# N32F030 register map
File version: 1.0
Registers are 32-bit, read-write, reset 0x0 unless marked. A register's access mark holds for its fields unless they carry their own. Offsets are from the block's base; [hi:lo] are bit positions.

## CLK — CLK Register Map
Base 0x50000200
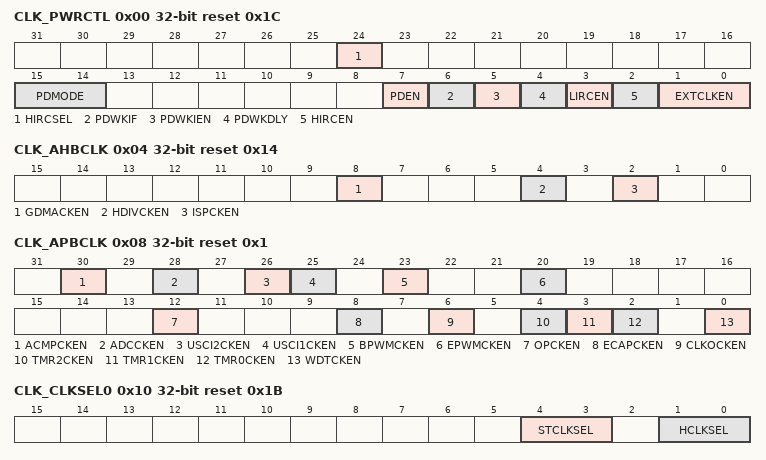
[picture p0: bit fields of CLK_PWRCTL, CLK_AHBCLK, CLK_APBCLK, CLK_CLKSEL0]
0x00 CLK_PWRCTL reset 0x1C — System Power-down Control Register
  [24] HIRCSEL — 0: Internal High Speed RC Oscillator Clock Will Output 48MHz. 1: Internal high speed RC oscillator clock will output 60MHz
  [15:14] PDMODE — 00: LDO Off When Power Down Mode. 01: LDO on when power down node
  [7] PDEN — System Power-down Enable Control (Write Protect). When this bit is set to 1, Power-down mode is enabled. When chip wakes up from Power-down mode, this bit is auto cleared. Users need to set this bit again for next Power-down. In Power-down mode, EXT_CLK and HIRC will be disabled. In Power-down mode, the system clocks are disabled, and ignored the clock source selection. The clocks of peripheral are not controlled by Power-down mode if the peripheral clock source is from LIRC. LIRC is controlled by bit LIRCEN. Note: This bit is write protected. Refer to the SYS_REGLCTL register.
    0=Chip operating normally or chip in idle mode because of WFI/WFE command; 1=Chip enters Power-down mode when CPU sleep command WFI/WFE
  [6] PDWKIF — Power-down Mode Wake-up Interrupt Status. Set by 'Power-down wake-up event', it indicates that resume from 'Power-down mode' The flag is set if the GPIO, USCIx, WDT, ACMPx, BOD, TMRx wake-up occurred. Note1: Write 1 to clear the bit to 0. Note2: This bit works only if PDWKIEN (CLK_PWRCTL[5]) set to 1.
  [5] PDWKIEN — Power-down Mode Wake-up Interrupt Enable Control (Write Protect). Note1: The interrupt will occur when both PDWKIF and PDWKIEN are high. Note2: This bit is write protected. Refer to the SYS_REGLCTL register.
    0=Power-down mode wake-up interrupt Disabled; 1=Power-down mode wake-up interrupt Enabled
  [4] PDWKDLY — Wake-up Delay Counter Enable Control (Write Protect). When the chip wakes up from Power-down mode, the clock control will delay certain clock cycles to wait system clock stable. The delayed clock cycle is 4096 clock cycles when chip works at external clock input(EXT_CLK), and 256 clock cycles when chip works at 48(60) MHz internal high speed RC oscillator (HIRC). Note: This bit is write protected. Refer to the SYS_REGLCTL register.
    0=Clock cycles delay Disabled; 1=Clock cycles delay Enabled
  [3] LIRCEN — LIRC Enable Control (Write Protect). Note: This bit is write protected. Refer to the SYS_REGLCTL register.
    0=10 kHz internal low speed RC oscillator (LIRC) Disabled; 1=10 kHz internal low speed RC oscillator (LIRC) Enabled
  [2] HIRCEN — HIRC Enable Control (Write Protect). Note: This bit is write protected. Refer to the SYS_REGLCTL register.
    0=48(60) MHz internal high speed RC oscillator (HIRC) Disabled; 1=48(60) MHz internal high speed RC oscillator (HIRC) Enabled
  [1:0] EXTCLKEN — External Clock Enable Control (Write Protect). These two bits are default set to '00' and EXT_CLK(PC.3) pins are GPIO. Note: This bit is write protected. Refer to the SYS_REGLCTL register.
    0=Disable external EXT_CLK; 3=Enable external EXT_CLK
0x04 CLK_AHBCLK reset 0x14 — AHB Devices Clock Enable Control Register
  [8] GDMACKEN — Gereral Direct Memory Access Controller Clock Enable Control
    0=GDMA clock Disabled; 1=GDMA clock Enabled
  [4] HDIVCKEN — Hardware Divider Controller Clock Enable Control
    0=HDIV peripheral clock Disabled; 1=HDIV peripheral clock Enabled
  [2] ISPCKEN — Flash ISP Controller Clock Enable Control
    0=Flash ISP peripheral clock Disabled; 1=Flash ISP peripheral clock Enabled
0x08 CLK_APBCLK reset 0x1 — APB Devices Clock Enable Control Register
  [30] ACMPCKEN — Analog Comparator Clock Enable Control
    0=Analog comparator clock Disabled; 1=Analog comparator clock Enabled
  [28] ADCCKEN — Analog-digital-converter (ADC) Clock Enable Control
    0=ADC clock Disabled; 1=ADC clock Enabled
  [26] USCI2CKEN — USCI2 Clock Enable Control
    0=USCI2 clock Disabled; 1=USCI2 clock Enabled
  [25] USCI1CKEN — USCI1 Clock Enable Control
    0=USCI1 clock Disabled; 1=USCI1 clock Enabled
  [23] BPWMCKEN — Basic PWM Channel 0/1 Clock Enable Control
    0=BBPWM channel 0/1 clock Disabled; 1=BPWM channel 0/1 clock Enabled
  [20] EPWMCKEN — Enhanced PWM Clock Enable Control
    0=EPWM channel 0/1 clock Disabled; 1=EPWM channel 0/1 clock Enabled
  [12] OPCKEN — OP Clock Enable Control
    0=OP clock Disabled; 1=OP clock Enabled
  [8] ECAPCKEN — Input Capture Clock Enable Control
    0=CAP clock Disabled; 1=CAP clock Enabled
  [6] CLKOCKEN — CLKO Clock Enable Control
    0=CLKO clock Disabled; 1=CLKO clock Enabled
  [4] TMR2CKEN — Timer2 Clock Enable Control
    0=Timer2 clock Disabled; 1=Timer2 clock Enabled
  [3] TMR1CKEN — Timer1 Clock Enable Control
    0=Timer1 clock Disabled; 1=Timer1 clock Enabled
  [2] TMR0CKEN — Timer0 Clock Enable Control
    0=Timer0 clock Disabled; 1=Timer0 clock Enabled
  [0] WDTCKEN — Watchdog Timer Clock Enable Control (Write Protect). Note: This bit is write protected. Refer to the SYS_REGLCTL register.
    0=Watchdog timer clock Disabled; 1=Watchdog timer clock Enabled
0x10 CLK_CLKSEL0 reset 0x1B — Clock Source Select Control Register 0
  [4:3] STCLKSEL — Cortex-M0 SysTick Clock Source Selection (Write Protect). Note: This bit is write protected. Refer to the SYS_REGLCTL register.
    0=Clock source from EXT_CLK; 1=Clock source from EXT_CLK/2; 2=Clock source from HCLK/2; 3=Clock source from HIRC/2
  [1:0] HCLKSEL — HCLK Clock Source Selection (Write Protect). Before clock switching, the related clock sources (both pre-select and new-select) must be turned on. Note: This bit is write protected. Refer to the SYS_REGLCTL register.
    0=Clock source from EXT_CLK; 1=Clock source from LIRC; 3=Clock source from HIRC
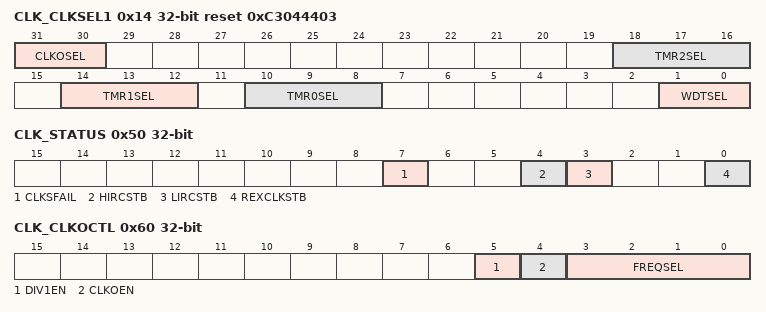
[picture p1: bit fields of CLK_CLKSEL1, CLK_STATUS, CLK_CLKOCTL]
0x14 CLK_CLKSEL1 reset 0xC3044403 — Clock Source Select Control Register 1
  [31:30] CLKOSEL — Clock Divider Clock Source Selection
    0=Clock source from external clock input (EXT_CLK); 2=Clock source from HCLK; 3=Clock source from 48(60) MHz internal high speed RC oscillator (HIRC)
  [18:16] TMR2SEL — TIMER2 Clock Source Selection
    0=Clock source from external clock input (EXT_CLK); 1=Clock source from 10 kHz internal low speed RC oscillator (LIRC); 2=Clock source from HCLK; 3=Clock source from external clock T2 pin; 4=Clock source from 48(60) MHz internal high speed RC oscillator (HIRC)
  [14:12] TMR1SEL — TIMER1 Clock Source Selection
    0=Clock source from external clock input (EXT_CLK); 1=Clock source from 10 kHz internal low speed RC oscillator (LIRC); 2=Clock source from HCLK; 3=Clock source from external clock T1 pin; 4=Clock source from 48(60) MHz internal high speed RC oscillator (HIRC)
  [10:8] TMR0SEL — TIMER0 Clock Source Selection
    0=Clock source from external clock input (EXT_CLK); 1=Clock source from 10 kHz internal low speed RC oscillator (LIRC); 2=Clock source from HCLK; 3=Clock source from external clock T0 pin; 4=Clock source from 48(60) MHz internal high speed RC oscillator (HIRC)
  [1:0] WDTSEL — Watchdog Timer Clock Source Selection (Write Protect). Note: This bit is write protected. Refer to the SYS_REGLCTL register.
    0=Clock source from external clock input (EXT_CLK); 2=Clock source from HCLK0/2048; 3=Clock source from 10 kHz internal low speed RC oscillator (LIRC)
0x20 CLK_CLKDIV — Clock Divider Number Register
  [3:0] HCLKDIV — HCLK Clock Divide Number From HCLK Clock Source
0x50 CLK_STATUS ro (reset mask 0xFFFFFF00) — Clock Status Monitor Register
  [7] CLKSFAIL — Clock Switching Fail Flag (Read Only). This bit is updated when software switches system clock source. If switch target clock is stable, this bit will be set to 0. If switch target clock is not stable, this bit will be set to 1. Note: Write 1 to clear the bit to 0.
    0=Clock switching success; 1=Clock switching failure
  [4] HIRCSTB — HIRC Clock Source Stable Flag (Read Only)
    0=48(60) MHz internal high speed RC oscillator (HIRC) clock is not stable or disabled; 1=48(60) MHz internal high speed RC oscillator (HIRC) clock is stable and enabled
  [3] LIRCSTB — LIRC Clock Source Stable Flag (Read Only)
    0=10 kHz internal low speed RC oscillator (LIRC) clock is not stable or disabled; 1=10 kHz internal low speed RC oscillator (LIRC) clock is stable and enabled
  [0] REXCLKSTB — External Clock Source Stable Flag (Read Only)
    0=External clock is not stable or disabled; 1=External clock is stable and enabled
0x60 CLK_CLKOCTL — Clock Output Control Register
  [5] DIV1EN — Clock Output Divide One Enable Control
    0=Clock Output will output clock with source frequency divided by FREQSEL; 1=Clock Output will output clock with source frequency
  [4] CLKOEN — Clock Output Enable Control
    0=Clock Output function Disabled; 1=Clock Output function Enabled
  [3:0] FREQSEL — Clock Output Frequency Selection. The formula of output frequency is. Fin is the input clock frequency. Fout is the frequency of divider output clock. N is the 4-bit value of FREQSEL[3:0].
